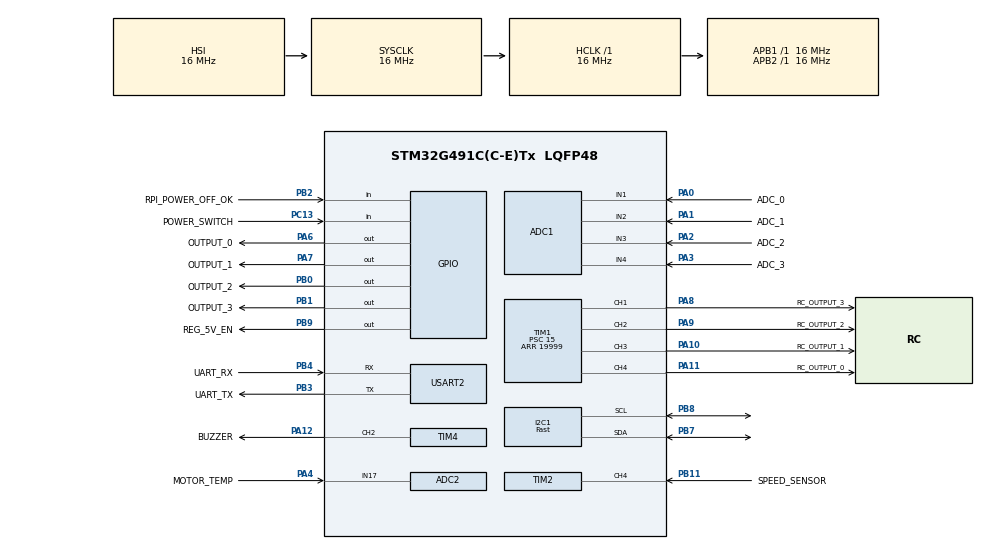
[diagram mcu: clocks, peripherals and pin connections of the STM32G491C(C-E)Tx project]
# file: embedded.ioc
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ADC1.Channel-1\#ChannelRegularConversion=ADC_CHANNEL_1
ADC1.Channel-2\#ChannelRegularConversion=ADC_CHANNEL_2
ADC1.Channel-3\#ChannelRegularConversion=ADC_CHANNEL_3
ADC1.Channel-4\#ChannelRegularConversion=ADC_CHANNEL_4
ADC1.ContinuousConvMode=DISABLE
ADC1.DMAContinuousRequests=ENABLE
ADC1.EOCSelection=ADC_EOC_SEQ_CONV
ADC1.ExternalTrigConv=ADC_EXTERNALTRIG_T6_TRGO
ADC1.NbrOfConversion=4
ADC1.NbrOfConversionFlag=1
ADC1.OffsetNumber-1\#ChannelRegularConversion=ADC_OFFSET_NONE
ADC1.OffsetNumber-2\#ChannelRegularConversion=ADC_OFFSET_NONE
ADC1.OffsetNumber-3\#ChannelRegularConversion=ADC_OFFSET_NONE
ADC1.OffsetNumber-4\#ChannelRegularConversion=ADC_OFFSET_NONE
ADC1.Rank-1\#ChannelRegularConversion=1
ADC1.Rank-2\#ChannelRegularConversion=2
ADC1.Rank-3\#ChannelRegularConversion=3
ADC1.Rank-4\#ChannelRegularConversion=4
ADC1.SamplingTime-1\#ChannelRegularConversion=ADC_SAMPLETIME_47CYCLES_5
ADC1.SamplingTime-2\#ChannelRegularConversion=ADC_SAMPLETIME_47CYCLES_5
ADC1.SamplingTime-3\#ChannelRegularConversion=ADC_SAMPLETIME_47CYCLES_5
ADC1.SamplingTime-4\#ChannelRegularConversion=ADC_SAMPLETIME_47CYCLES_5
ADC1.master=1
ADC2.Channel-0\#ChannelRegularConversion=ADC_CHANNEL_17
ADC2.ContinuousConvMode=DISABLE
ADC2.NbrOfConversionFlag=1
ADC2.OffsetNumber-0\#ChannelRegularConversion=ADC_OFFSET_NONE
ADC2.Rank-0\#ChannelRegularConversion=1
ADC2.SamplingTime-0\#ChannelRegularConversion=ADC_SAMPLETIME_92CYCLES_5
Dma.ADC1.0.Direction=DMA_PERIPH_TO_MEMORY
Dma.ADC1.0.EventEnable=DISABLE
Dma.ADC1.0.Instance=DMA1_Channel1
Dma.ADC1.0.MemDataAlignment=DMA_MDATAALIGN_HALFWORD
Dma.ADC1.0.MemInc=DMA_MINC_ENABLE
Dma.ADC1.0.Mode=DMA_CIRCULAR
Dma.ADC1.0.PeriphDataAlignment=DMA_PDATAALIGN_HALFWORD
Dma.ADC1.0.PeriphInc=DMA_PINC_DISABLE
Dma.ADC1.0.Polarity=HAL_DMAMUX_REQ_GEN_RISING
Dma.ADC1.0.Priority=DMA_PRIORITY_LOW
Dma.ADC1.0.RequestNumber=1
Dma.ADC1.0.SignalID=NONE
Dma.ADC1.0.SyncEnable=DISABLE
Dma.ADC1.0.SyncPolarity=HAL_DMAMUX_SYNC_NO_EVENT
Dma.ADC1.0.SyncRequestNumber=1
Dma.ADC1.0.SyncSignalID=NONE
Dma.Request0=ADC1
Dma.Request1=USART2_TX
Dma.USART2_TX.1.Direction=DMA_MEMORY_TO_PERIPH
Dma.USART2_TX.1.EventEnable=DISABLE
Dma.USART2_TX.1.Instance=DMA1_Channel3
Dma.USART2_TX.1.MemDataAlignment=DMA_MDATAALIGN_BYTE
Dma.USART2_TX.1.MemInc=DMA_MINC_ENABLE
Dma.USART2_TX.1.Mode=DMA_NORMAL
Dma.USART2_TX.1.PeriphDataAlignment=DMA_PDATAALIGN_BYTE
Dma.USART2_TX.1.PeriphInc=DMA_PINC_DISABLE
Dma.USART2_TX.1.Polarity=HAL_DMAMUX_REQ_GEN_RISING
Dma.USART2_TX.1.Priority=DMA_PRIORITY_LOW
Dma.USART2_TX.1.RequestNumber=1
Dma.USART2_TX.1.SignalID=NONE
Dma.USART2_TX.1.SyncEnable=DISABLE
Dma.USART2_TX.1.SyncPolarity=HAL_DMAMUX_SYNC_NO_EVENT
Dma.USART2_TX.1.SyncRequestNumber=1
Dma.USART2_TX.1.SyncSignalID=NONE
I2C1.I2C_Speed_Mode=I2C_Fast
I2C1.NoStretchMode=I2C_NOSTRETCH_DISABLE
I2C1.Timing=0x00300617
Mcu.Family=STM32G4
Mcu.Name=STM32G491C(C-E)Tx
Mcu.Package=LQFP48
NVIC.DMA1_Channel1_IRQn=true\:0\:0\:false\:false\:true\:false\:true\:true
NVIC.DMA1_Channel3_IRQn=true\:0\:0\:false\:false\:true\:false\:true\:true
NVIC.I2C1_ER_IRQn=true\:5\:0\:false\:false\:true\:true\:true\:true
NVIC.I2C1_EV_IRQn=true\:5\:0\:false\:false\:true\:true\:true\:true
NVIC.PriorityGroup=NVIC_PRIORITYGROUP_4
NVIC.TIM2_IRQn=true\:0\:0\:false\:false\:true\:true\:true\:true
NVIC.USART2_IRQn=true\:0\:0\:false\:false\:true\:true\:true\:true
PA0.GPIO_Label=ADC_0
PA0.Mode=IN1-Single-Ended
PA0.Signal=ADC1_IN1
PA1.GPIO_Label=ADC_1
PA1.Mode=IN2-Single-Ended
PA1.Signal=ADC1_IN2
PA10.GPIO_Label=RC_OUTPUT_1
PA10.Signal=S_TIM1_CH3
PA11.GPIO_Label=RC_OUTPUT_0
PA11.Signal=S_TIM1_CH4
PA12.GPIO_Label=BUZZER
PA12.Signal=S_TIM4_CH2
PA2.GPIO_Label=ADC_2
PA2.Mode=IN3-Single-Ended
PA2.Signal=ADC1_IN3
PA3.GPIO_Label=ADC_3
PA3.Mode=IN4-Single-Ended
PA3.Signal=ADC1_IN4
PA4.GPIO_Label=MOTOR_TEMP
PA4.Mode=IN17-Single-Ended
PA4.Signal=ADC2_IN17
PA6.GPIO_Label=OUTPUT_0
PA6.Signal=GPIO_Output
PA7.GPIO_Label=OUTPUT_1
PA7.Signal=GPIO_Output
PA8.GPIO_Label=RC_OUTPUT_3
PA8.Signal=S_TIM1_CH1
PA9.GPIO_Label=RC_OUTPUT_2
PA9.Signal=S_TIM1_CH2
PB0.GPIO_Label=OUTPUT_2
PB0.Signal=GPIO_Output
PB1.GPIO_Label=OUTPUT_3
PB1.Signal=GPIO_Output
PB11.GPIO_Label=SPEED_SENSOR
PB11.GPIO_PuPd=GPIO_PULLUP
PB11.Signal=S_TIM2_CH4
PB2.GPIO_Label=RPI_POWER_OFF_OK
PB2.Signal=GPIO_Input
PB3.GPIO_Label=UART_TX
PB3.Mode=Asynchronous
PB3.Signal=USART2_TX
PB4.GPIO_Label=UART_RX
PB4.Mode=Asynchronous
PB4.Signal=USART2_RX
PB7.Mode=I2C
PB7.Signal=I2C1_SDA
PB8-BOOT0.Mode=I2C
PB8-BOOT0.Signal=I2C1_SCL
PB9.GPIO_Label=REG_5V_EN
PB9.Signal=GPIO_Output
PC13.GPIO_Label=POWER_SWITCH
PC13.Signal=GPIO_Input
ProjectManager.HeapSize=0x200
ProjectManager.StackSize=0x400
ProjectManager.TargetToolchain=STM32CubeIDE
RCC.AHBFreq_Value=16000000
RCC.APB1Freq_Value=16000000
RCC.APB1TimFreq_Value=16000000
RCC.APB2Freq_Value=16000000
RCC.APB2TimFreq_Value=16000000
RCC.CortexFreq_Value=16000000
RCC.EXTERNAL_CLOCK_VALUE=12288000
RCC.HCLKFreq_Value=16000000
RCC.HSE_VALUE=8000000
RCC.HSI48_VALUE=48000000
RCC.HSI_VALUE=16000000
RCC.LSE_VALUE=32768
RCC.SYSCLKFreq_VALUE=16000000
RCC.VCOOutputFreq_Value=128000000
SH.S_TIM1_CH1.0=TIM1_CH1,PWM Generation1 CH1
SH.S_TIM1_CH2.0=TIM1_CH2,PWM Generation2 CH2
SH.S_TIM1_CH3.0=TIM1_CH3,PWM Generation3 CH3
SH.S_TIM1_CH4.0=TIM1_CH4,PWM Generation4 CH4
SH.S_TIM2_CH4.0=TIM2_CH4,Input_Capture4_from_TI4
SH.S_TIM4_CH2.0=TIM4_CH2,PWM Generation2 CH2
TIM1.AutoReloadPreload=TIM_AUTORELOAD_PRELOAD_ENABLE
TIM1.Channel-PWM\ Generation1\ CH1=TIM_CHANNEL_1
TIM1.Channel-PWM\ Generation2\ CH2=TIM_CHANNEL_2
TIM1.Channel-PWM\ Generation3\ CH3=TIM_CHANNEL_3
TIM1.Channel-PWM\ Generation4\ CH4=TIM_CHANNEL_4
TIM1.PeriodNoDither=19999
TIM1.Prescaler=15
TIM1.PulseNoDither_1=1500
TIM1.PulseNoDither_2=1500
TIM1.PulseNoDither_3=1500
TIM1.PulseNoDither_4=1500
TIM2.Channel-Input_Capture4_from_TI4=TIM_CHANNEL_4
TIM2.ICFilter_CH4=4
TIM2.ICPolarity_CH4=TIM_INPUTCHANNELPOLARITY_FALLING
TIM2.Prescaler=15
TIM4.Channel-PWM\ Generation2\ CH2=TIM_CHANNEL_2
TIM4.PeriodNoDither=249
TIM4.Prescaler=15
TIM6.PeriodNoDither=999
TIM6.Prescaler=159
TIM6.TIM_MasterOutputTrigger=TIM_TRGO_UPDATE
USART2.VirtualMode-Asynchronous=VM_ASYNC
VP_SYS_VS_DBSignals.Mode=DisableDeadBatterySignals
VP_TIM1_VS_ClockSourceINT.Mode=Internal
VP_TIM2_VS_ClockSourceINT.Mode=Internal
VP_TIM4_VS_ClockSourceINT.Mode=Internal
VP_TIM6_VS_ClockSourceINT.Mode=Enable_Timer
board=custom

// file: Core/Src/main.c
/* USER CODE BEGIN Header */
/**
  ******************************************************************************
  * @file           : main.c
  * @brief          : Main program body
  ******************************************************************************
  * @attention
  *
  * Copyright (c) 2026 STMicroelectronics.
  * All rights reserved.
  *
  * This software is licensed under terms that can be found in the LICENSE file
  * in the root directory of this software component.
  * If no LICENSE file comes with this software, it is provided AS-IS.
  *
  ******************************************************************************
  */
/* USER CODE END Header */
#include "main.h"

/* USER CODE BEGIN Includes */
#include "app.h"
#include "adc_task.h"
#include "speed_task.h"
#include "uart_task.h"

/* USER CODE END Includes */

ADC_HandleTypeDef hadc1;
ADC_HandleTypeDef hadc2;
DMA_HandleTypeDef hdma_adc1;

I2C_HandleTypeDef hi2c1;

TIM_HandleTypeDef htim1;
TIM_HandleTypeDef htim2;
TIM_HandleTypeDef htim4;
TIM_HandleTypeDef htim6;

UART_HandleTypeDef huart2;
DMA_HandleTypeDef hdma_usart2_tx;

void SystemClock_Config(void);
static void MX_GPIO_Init(void);
static void MX_DMA_Init(void);
static void MX_ADC1_Init(void);
static void MX_ADC2_Init(void);
static void MX_TIM1_Init(void);
static void MX_TIM2_Init(void);
static void MX_TIM4_Init(void);
static void MX_I2C1_Init(void);
static void MX_USART2_UART_Init(void);
static void MX_TIM6_Init(void);

int main(void)
{

  /* MCU Configuration--------------------------------------------------------*/

  /* Reset of all peripherals, Initializes the Flash interface and the Systick. */
  HAL_Init();

  /* Configure the system clock */
  SystemClock_Config();

  /* Initialize all configured peripherals */
  MX_GPIO_Init();
  MX_DMA_Init();
  MX_ADC1_Init();
  MX_ADC2_Init();
  MX_TIM1_Init();
  MX_TIM2_Init();
  MX_TIM4_Init();
  MX_I2C1_Init();
  MX_USART2_UART_Init();
  MX_TIM6_Init();
  /* USER CODE BEGIN 2 */
  app_init();

  /* USER CODE END 2 */

  /* Infinite loop */
  while (1)
  {

    /* USER CODE BEGIN 3 */
    app_run();
  }
  /* USER CODE END 3 */
}

void SystemClock_Config(void)
{
  RCC_OscInitTypeDef RCC_OscInitStruct = {0};
  RCC_ClkInitTypeDef RCC_ClkInitStruct = {0};

  /** Configure the main internal regulator output voltage
  */
  HAL_PWREx_ControlVoltageScaling(PWR_REGULATOR_VOLTAGE_SCALE1);

  /** Initializes the RCC Oscillators according to the specified parameters
  * in the RCC_OscInitTypeDef structure.
  */
  RCC_OscInitStruct.OscillatorType = RCC_OSCILLATORTYPE_HSI;
  RCC_OscInitStruct.HSIState = RCC_HSI_ON;
  RCC_OscInitStruct.HSICalibrationValue = RCC_HSICALIBRATION_DEFAULT;
  RCC_OscInitStruct.PLL.PLLState = RCC_PLL_NONE;
  if (HAL_RCC_OscConfig(&RCC_OscInitStruct) != HAL_OK)
  {
    Error_Handler();
  }

  /** Initializes the CPU, AHB and APB buses clocks
  */
  RCC_ClkInitStruct.ClockType = RCC_CLOCKTYPE_HCLK|RCC_CLOCKTYPE_SYSCLK
                              |RCC_CLOCKTYPE_PCLK1|RCC_CLOCKTYPE_PCLK2;
  RCC_ClkInitStruct.SYSCLKSource = RCC_SYSCLKSOURCE_HSI;
  RCC_ClkInitStruct.AHBCLKDivider = RCC_SYSCLK_DIV1;
  RCC_ClkInitStruct.APB1CLKDivider = RCC_HCLK_DIV1;
  RCC_ClkInitStruct.APB2CLKDivider = RCC_HCLK_DIV1;

  if (HAL_RCC_ClockConfig(&RCC_ClkInitStruct, FLASH_LATENCY_0) != HAL_OK)
  {
    Error_Handler();
  }
}

static void MX_ADC1_Init(void)
{

  ADC_MultiModeTypeDef multimode = {0};
  ADC_ChannelConfTypeDef sConfig = {0};

  /** Common config
  */
  hadc1.Instance = ADC1;
  hadc1.Init.ClockPrescaler = ADC_CLOCK_SYNC_PCLK_DIV2;
  hadc1.Init.Resolution = ADC_RESOLUTION_12B;
  hadc1.Init.DataAlign = ADC_DATAALIGN_RIGHT;
  hadc1.Init.GainCompensation = 0;
  hadc1.Init.ScanConvMode = ADC_SCAN_ENABLE;
  hadc1.Init.EOCSelection = ADC_EOC_SEQ_CONV;
  hadc1.Init.LowPowerAutoWait = DISABLE;
  hadc1.Init.ContinuousConvMode = DISABLE;
  hadc1.Init.NbrOfConversion = 4;
  hadc1.Init.DiscontinuousConvMode = DISABLE;
  hadc1.Init.ExternalTrigConv = ADC_EXTERNALTRIG_T6_TRGO;
  hadc1.Init.ExternalTrigConvEdge = ADC_EXTERNALTRIGCONVEDGE_RISING;
  hadc1.Init.DMAContinuousRequests = ENABLE;
  hadc1.Init.Overrun = ADC_OVR_DATA_PRESERVED;
  hadc1.Init.OversamplingMode = DISABLE;
  if (HAL_ADC_Init(&hadc1) != HAL_OK)
  {
    Error_Handler();
  }

  /** Configure the ADC multi-mode
  */
  multimode.Mode = ADC_MODE_INDEPENDENT;
  if (HAL_ADCEx_MultiModeConfigChannel(&hadc1, &multimode) != HAL_OK)
  {
    Error_Handler();
  }

  /** Configure Regular Channel
  */
  sConfig.Channel = ADC_CHANNEL_1;
  sConfig.Rank = ADC_REGULAR_RANK_1;
  sConfig.SamplingTime = ADC_SAMPLETIME_47CYCLES_5;
  sConfig.SingleDiff = ADC_SINGLE_ENDED;
  sConfig.OffsetNumber = ADC_OFFSET_NONE;
  sConfig.Offset = 0;
  if (HAL_ADC_ConfigChannel(&hadc1, &sConfig) != HAL_OK)
  {
    Error_Handler();
  }

  /** Configure Regular Channel
  */
  sConfig.Channel = ADC_CHANNEL_2;
  sConfig.Rank = ADC_REGULAR_RANK_2;
  if (HAL_ADC_ConfigChannel(&hadc1, &sConfig) != HAL_OK)
  {
    Error_Handler();
  }

  /** Configure Regular Channel
  */
  sConfig.Channel = ADC_CHANNEL_3;
  sConfig.Rank = ADC_REGULAR_RANK_3;
  if (HAL_ADC_ConfigChannel(&hadc1, &sConfig) != HAL_OK)
  {
    Error_Handler();
  }

  /** Configure Regular Channel
  */
  sConfig.Channel = ADC_CHANNEL_4;
  sConfig.Rank = ADC_REGULAR_RANK_4;
  if (HAL_ADC_ConfigChannel(&hadc1, &sConfig) != HAL_OK)
  {
    Error_Handler();
  }

}

static void MX_ADC2_Init(void)
{

  ADC_ChannelConfTypeDef sConfig = {0};

  /** Common config
  */
  hadc2.Instance = ADC2;
  hadc2.Init.ClockPrescaler = ADC_CLOCK_SYNC_PCLK_DIV2;
  hadc2.Init.Resolution = ADC_RESOLUTION_12B;
  hadc2.Init.DataAlign = ADC_DATAALIGN_RIGHT;
  hadc2.Init.GainCompensation = 0;
  hadc2.Init.ScanConvMode = ADC_SCAN_DISABLE;
  hadc2.Init.EOCSelection = ADC_EOC_SINGLE_CONV;
  hadc2.Init.LowPowerAutoWait = DISABLE;
  hadc2.Init.ContinuousConvMode = DISABLE;
  hadc2.Init.NbrOfConversion = 1;
  hadc2.Init.DiscontinuousConvMode = DISABLE;
  hadc2.Init.ExternalTrigConv = ADC_SOFTWARE_START;
  hadc2.Init.ExternalTrigConvEdge = ADC_EXTERNALTRIGCONVEDGE_NONE;
  hadc2.Init.DMAContinuousRequests = DISABLE;
  hadc2.Init.Overrun = ADC_OVR_DATA_PRESERVED;
  hadc2.Init.OversamplingMode = DISABLE;
  if (HAL_ADC_Init(&hadc2) != HAL_OK)
  {
    Error_Handler();
  }

  /** Configure Regular Channel
  */
  sConfig.Channel = ADC_CHANNEL_17;
  sConfig.Rank = ADC_REGULAR_RANK_1;
  sConfig.SamplingTime = ADC_SAMPLETIME_92CYCLES_5;
  sConfig.SingleDiff = ADC_SINGLE_ENDED;
  sConfig.OffsetNumber = ADC_OFFSET_NONE;
  sConfig.Offset = 0;
  if (HAL_ADC_ConfigChannel(&hadc2, &sConfig) != HAL_OK)
  {
    Error_Handler();
  }

}

static void MX_I2C1_Init(void)
{

  hi2c1.Instance = I2C1;
  hi2c1.Init.Timing = 0x00300617;
  hi2c1.Init.OwnAddress1 = 0;
  hi2c1.Init.AddressingMode = I2C_ADDRESSINGMODE_7BIT;
  hi2c1.Init.DualAddressMode = I2C_DUALADDRESS_DISABLE;
  hi2c1.Init.OwnAddress2 = 0;
  hi2c1.Init.OwnAddress2Masks = I2C_OA2_NOMASK;
  hi2c1.Init.GeneralCallMode = I2C_GENERALCALL_DISABLE;
  hi2c1.Init.NoStretchMode = I2C_NOSTRETCH_DISABLE;
  if (HAL_I2C_Init(&hi2c1) != HAL_OK)
  {
    Error_Handler();
  }

  /** Configure Analogue filter
  */
  if (HAL_I2CEx_ConfigAnalogFilter(&hi2c1, I2C_ANALOGFILTER_ENABLE) != HAL_OK)
  {
    Error_Handler();
  }

  /** Configure Digital filter
  */
  if (HAL_I2CEx_ConfigDigitalFilter(&hi2c1, 0) != HAL_OK)
  {
    Error_Handler();
  }

}

static void MX_TIM1_Init(void)
{

  TIM_ClockConfigTypeDef sClockSourceConfig = {0};
  TIM_MasterConfigTypeDef sMasterConfig = {0};
  TIM_OC_InitTypeDef sConfigOC = {0};
  TIM_BreakDeadTimeConfigTypeDef sBreakDeadTimeConfig = {0};

  htim1.Instance = TIM1;
  htim1.Init.Prescaler = 15;
  htim1.Init.CounterMode = TIM_COUNTERMODE_UP;
  htim1.Init.Period = 19999;
  htim1.Init.ClockDivision = TIM_CLOCKDIVISION_DIV1;
  htim1.Init.RepetitionCounter = 0;
  htim1.Init.AutoReloadPreload = TIM_AUTORELOAD_PRELOAD_ENABLE;
  if (HAL_TIM_Base_Init(&htim1) != HAL_OK)
  {
    Error_Handler();
  }
  sClockSourceConfig.ClockSource = TIM_CLOCKSOURCE_INTERNAL;
  if (HAL_TIM_ConfigClockSource(&htim1, &sClockSourceConfig) != HAL_OK)
  {
    Error_Handler();
  }
  if (HAL_TIM_PWM_Init(&htim1) != HAL_OK)
  {
    Error_Handler();
  }
  sMasterConfig.MasterOutputTrigger = TIM_TRGO_RESET;
  sMasterConfig.MasterOutputTrigger2 = TIM_TRGO2_RESET;
  sMasterConfig.MasterSlaveMode = TIM_MASTERSLAVEMODE_DISABLE;
  if (HAL_TIMEx_MasterConfigSynchronization(&htim1, &sMasterConfig) != HAL_OK)
  {
    Error_Handler();
  }
  sConfigOC.OCMode = TIM_OCMODE_PWM1;
  sConfigOC.Pulse = 1500;
  sConfigOC.OCPolarity = TIM_OCPOLARITY_HIGH;
  sConfigOC.OCNPolarity = TIM_OCNPOLARITY_HIGH;
  sConfigOC.OCFastMode = TIM_OCFAST_DISABLE;
  sConfigOC.OCIdleState = TIM_OCIDLESTATE_RESET;
  sConfigOC.OCNIdleState = TIM_OCNIDLESTATE_RESET;
  if (HAL_TIM_PWM_ConfigChannel(&htim1, &sConfigOC, TIM_CHANNEL_1) != HAL_OK)
  {
    Error_Handler();
  }
  if (HAL_TIM_PWM_ConfigChannel(&htim1, &sConfigOC, TIM_CHANNEL_2) != HAL_OK)
  {
    Error_Handler();
  }
  if (HAL_TIM_PWM_ConfigChannel(&htim1, &sConfigOC, TIM_CHANNEL_3) != HAL_OK)
  {
    Error_Handler();
  }
  if (HAL_TIM_PWM_ConfigChannel(&htim1, &sConfigOC, TIM_CHANNEL_4) != HAL_OK)
  {
    Error_Handler();
  }
  sBreakDeadTimeConfig.OffStateRunMode = TIM_OSSR_DISABLE;
  sBreakDeadTimeConfig.OffStateIDLEMode = TIM_OSSI_DISABLE;
  sBreakDeadTimeConfig.LockLevel = TIM_LOCKLEVEL_OFF;
  sBreakDeadTimeConfig.DeadTime = 0;
  sBreakDeadTimeConfig.BreakState = TIM_BREAK_DISABLE;
  sBreakDeadTimeConfig.BreakPolarity = TIM_BREAKPOLARITY_HIGH;
  sBreakDeadTimeConfig.BreakFilter = 0;
  sBreakDeadTimeConfig.BreakAFMode = TIM_BREAK_AFMODE_INPUT;
  sBreakDeadTimeConfig.Break2State = TIM_BREAK2_DISABLE;
  sBreakDeadTimeConfig.Break2Polarity = TIM_BREAK2POLARITY_HIGH;
  sBreakDeadTimeConfig.Break2Filter = 0;
  sBreakDeadTimeConfig.Break2AFMode = TIM_BREAK_AFMODE_INPUT;
  sBreakDeadTimeConfig.AutomaticOutput = TIM_AUTOMATICOUTPUT_DISABLE;
  if (HAL_TIMEx_ConfigBreakDeadTime(&htim1, &sBreakDeadTimeConfig) != HAL_OK)
  {
    Error_Handler();
  }
  HAL_TIM_MspPostInit(&htim1);

}

static void MX_TIM2_Init(void)
{

  TIM_ClockConfigTypeDef sClockSourceConfig = {0};
  TIM_MasterConfigTypeDef sMasterConfig = {0};
  TIM_IC_InitTypeDef sConfigIC = {0};

  htim2.Instance = TIM2;
  htim2.Init.Prescaler = 15;
  htim2.Init.CounterMode = TIM_COUNTERMODE_UP;
  htim2.Init.Period = 4294967295;
  htim2.Init.ClockDivision = TIM_CLOCKDIVISION_DIV1;
  htim2.Init.AutoReloadPreload = TIM_AUTORELOAD_PRELOAD_DISABLE;
  if (HAL_TIM_Base_Init(&htim2) != HAL_OK)
  {
    Error_Handler();
  }
  sClockSourceConfig.ClockSource = TIM_CLOCKSOURCE_INTERNAL;
  if (HAL_TIM_ConfigClockSource(&htim2, &sClockSourceConfig) != HAL_OK)
  {
    Error_Handler();
  }
  if (HAL_TIM_IC_Init(&htim2) != HAL_OK)
  {
    Error_Handler();
  }
  sMasterConfig.MasterOutputTrigger = TIM_TRGO_RESET;
  sMasterConfig.MasterSlaveMode = TIM_MASTERSLAVEMODE_DISABLE;
  if (HAL_TIMEx_MasterConfigSynchronization(&htim2, &sMasterConfig) != HAL_OK)
  {
    Error_Handler();
  }
  sConfigIC.ICPolarity = TIM_INPUTCHANNELPOLARITY_FALLING;
  sConfigIC.ICSelection = TIM_ICSELECTION_DIRECTTI;
  sConfigIC.ICPrescaler = TIM_ICPSC_DIV1;
  sConfigIC.ICFilter = 4;
  if (HAL_TIM_IC_ConfigChannel(&htim2, &sConfigIC, TIM_CHANNEL_4) != HAL_OK)
  {
    Error_Handler();
  }

}

static void MX_TIM4_Init(void)
{

  TIM_ClockConfigTypeDef sClockSourceConfig = {0};
  TIM_MasterConfigTypeDef sMasterConfig = {0};
  TIM_OC_InitTypeDef sConfigOC = {0};

  htim4.Instance = TIM4;
  htim4.Init.Prescaler = 15;
  htim4.Init.CounterMode = TIM_COUNTERMODE_UP;
  htim4.Init.Period = 249;
  htim4.Init.ClockDivision = TIM_CLOCKDIVISION_DIV1;
  htim4.Init.AutoReloadPreload = TIM_AUTORELOAD_PRELOAD_DISABLE;
  if (HAL_TIM_Base_Init(&htim4) != HAL_OK)
  {
    Error_Handler();
  }
  sClockSourceConfig.ClockSource = TIM_CLOCKSOURCE_INTERNAL;
  if (HAL_TIM_ConfigClockSource(&htim4, &sClockSourceConfig) != HAL_OK)
  {
    Error_Handler();
  }
  if (HAL_TIM_PWM_Init(&htim4) != HAL_OK)
  {
    Error_Handler();
  }
  sMasterConfig.MasterOutputTrigger = TIM_TRGO_RESET;
  sMasterConfig.MasterSlaveMode = TIM_MASTERSLAVEMODE_DISABLE;
  if (HAL_TIMEx_MasterConfigSynchronization(&htim4, &sMasterConfig) != HAL_OK)
  {
    Error_Handler();
  }
  sConfigOC.OCMode = TIM_OCMODE_PWM1;
  sConfigOC.Pulse = 0;
  sConfigOC.OCPolarity = TIM_OCPOLARITY_HIGH;
  sConfigOC.OCFastMode = TIM_OCFAST_DISABLE;
  if (HAL_TIM_PWM_ConfigChannel(&htim4, &sConfigOC, TIM_CHANNEL_2) != HAL_OK)
  {
    Error_Handler();
  }
  HAL_TIM_MspPostInit(&htim4);

}

static void MX_TIM6_Init(void)
{

  TIM_MasterConfigTypeDef sMasterConfig = {0};

  htim6.Instance = TIM6;
  htim6.Init.Prescaler = 159;
  htim6.Init.CounterMode = TIM_COUNTERMODE_UP;
  htim6.Init.Period = 999;
  htim6.Init.AutoReloadPreload = TIM_AUTORELOAD_PRELOAD_DISABLE;
  if (HAL_TIM_Base_Init(&htim6) != HAL_OK)
  {
    Error_Handler();
  }
  sMasterConfig.MasterOutputTrigger = TIM_TRGO_UPDATE;
  sMasterConfig.MasterSlaveMode = TIM_MASTERSLAVEMODE_DISABLE;
  if (HAL_TIMEx_MasterConfigSynchronization(&htim6, &sMasterConfig) != HAL_OK)
  {
    Error_Handler();
  }

}

static void MX_USART2_UART_Init(void)
{

  huart2.Instance = USART2;
  huart2.Init.BaudRate = 115200;
  huart2.Init.WordLength = UART_WORDLENGTH_8B;
  huart2.Init.StopBits = UART_STOPBITS_1;
  huart2.Init.Parity = UART_PARITY_NONE;
  huart2.Init.Mode = UART_MODE_TX_RX;
  huart2.Init.HwFlowCtl = UART_HWCONTROL_NONE;
  huart2.Init.OverSampling = UART_OVERSAMPLING_16;
  huart2.Init.OneBitSampling = UART_ONE_BIT_SAMPLE_DISABLE;
  huart2.Init.ClockPrescaler = UART_PRESCALER_DIV1;
  huart2.AdvancedInit.AdvFeatureInit = UART_ADVFEATURE_NO_INIT;
  if (HAL_UART_Init(&huart2) != HAL_OK)
  {
    Error_Handler();
  }
  if (HAL_UARTEx_SetTxFifoThreshold(&huart2, UART_TXFIFO_THRESHOLD_1_8) != HAL_OK)
  {
    Error_Handler();
  }
  if (HAL_UARTEx_SetRxFifoThreshold(&huart2, UART_RXFIFO_THRESHOLD_1_8) != HAL_OK)
  {
    Error_Handler();
  }
  if (HAL_UARTEx_DisableFifoMode(&huart2) != HAL_OK)
  {
    Error_Handler();
  }

}

static void MX_DMA_Init(void)
{

  /* DMA controller clock enable */
  __HAL_RCC_DMAMUX1_CLK_ENABLE();
  __HAL_RCC_DMA1_CLK_ENABLE();

  /* DMA interrupt init */
  /* DMA1_Channel1_IRQn interrupt configuration */
  HAL_NVIC_SetPriority(DMA1_Channel1_IRQn, 0, 0);
  HAL_NVIC_EnableIRQ(DMA1_Channel1_IRQn);
  /* DMA1_Channel3_IRQn interrupt configuration */
  HAL_NVIC_SetPriority(DMA1_Channel3_IRQn, 0, 0);
  HAL_NVIC_EnableIRQ(DMA1_Channel3_IRQn);

}

static void MX_GPIO_Init(void)
{
  GPIO_InitTypeDef GPIO_InitStruct = {0};

  /* GPIO Ports Clock Enable */
  __HAL_RCC_GPIOC_CLK_ENABLE();
  __HAL_RCC_GPIOA_CLK_ENABLE();
  __HAL_RCC_GPIOB_CLK_ENABLE();

  /*Configure GPIO pin Output Level */
  HAL_GPIO_WritePin(GPIOA, OUTPUT_0_Pin|OUTPUT_1_Pin, GPIO_PIN_RESET);

  /*Configure GPIO pin Output Level */
  HAL_GPIO_WritePin(GPIOB, OUTPUT_2_Pin|OUTPUT_3_Pin|REG_5V_EN_Pin, GPIO_PIN_RESET);

  /*Configure GPIO pin : POWER_SWITCH_Pin */
  GPIO_InitStruct.Pin = POWER_SWITCH_Pin;
  GPIO_InitStruct.Mode = GPIO_MODE_INPUT;
  GPIO_InitStruct.Pull = GPIO_NOPULL;
  HAL_GPIO_Init(POWER_SWITCH_GPIO_Port, &GPIO_InitStruct);

  /*Configure GPIO pins : OUTPUT_0_Pin OUTPUT_1_Pin */
  GPIO_InitStruct.Pin = OUTPUT_0_Pin|OUTPUT_1_Pin;
  GPIO_InitStruct.Mode = GPIO_MODE_OUTPUT_PP;
  GPIO_InitStruct.Pull = GPIO_NOPULL;
  GPIO_InitStruct.Speed = GPIO_SPEED_FREQ_LOW;
  HAL_GPIO_Init(GPIOA, &GPIO_InitStruct);

  /*Configure GPIO pins : OUTPUT_2_Pin OUTPUT_3_Pin REG_5V_EN_Pin */
  GPIO_InitStruct.Pin = OUTPUT_2_Pin|OUTPUT_3_Pin|REG_5V_EN_Pin;
  GPIO_InitStruct.Mode = GPIO_MODE_OUTPUT_PP;
  GPIO_InitStruct.Pull = GPIO_NOPULL;
  GPIO_InitStruct.Speed = GPIO_SPEED_FREQ_LOW;
  HAL_GPIO_Init(GPIOB, &GPIO_InitStruct);

  /*Configure GPIO pin : RPI_POWER_OFF_OK_Pin */
  GPIO_InitStruct.Pin = RPI_POWER_OFF_OK_Pin;
  GPIO_InitStruct.Mode = GPIO_MODE_INPUT;
  GPIO_InitStruct.Pull = GPIO_NOPULL;
  HAL_GPIO_Init(RPI_POWER_OFF_OK_GPIO_Port, &GPIO_InitStruct);

}

/* USER CODE BEGIN 4 */
void HAL_ADC_ConvCpltCallback(ADC_HandleTypeDef *hadc)
{
  adc_task_dma_full_callback(hadc);
}

void HAL_UART_RxCpltCallback(UART_HandleTypeDef *huart)
{
  uart_task_rx_complete_callback(huart);
}

void HAL_UART_ErrorCallback(UART_HandleTypeDef *huart)
{
  uart_task_error_callback(huart);
}

void HAL_TIM_IC_CaptureCallback(TIM_HandleTypeDef *htim)
{
  speed_task_capture_callback(htim);
}

/* USER CODE END 4 */

void Error_Handler(void)
{
  __disable_irq();
  while (1)
  {
  }
}
